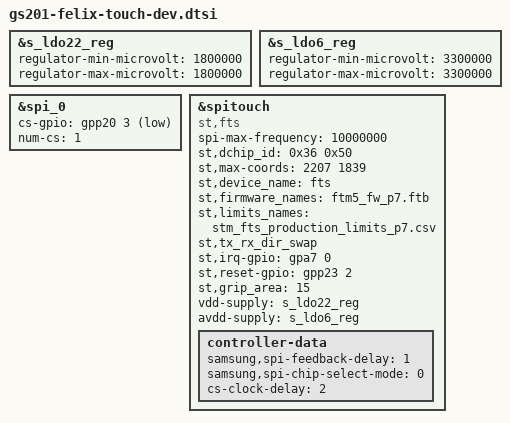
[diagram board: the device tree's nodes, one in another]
// SPDX-License-Identifier: GPL-2.0-only
/*
 * Google L10 touch device tree source
 *
 * Copyright 2022 Google Inc.
 *
 */

#include <arm64/exynos/exynos-pinctrl.h>

&s_ldo22_reg {
	regulator-min-microvolt = <1800000>;
	regulator-max-microvolt = <1800000>;
	/delete-property/ regulator-always-on;
};

&s_ldo6_reg {
	regulator-min-microvolt = <3300000>;
	regulator-max-microvolt = <3300000>;
	/delete-property/ regulator-always-on;
};

&spi_0 {
	cs-gpio = <&gpp20 3 GPIO_ACTIVE_LOW>;
	num-cs = <1>;
};

&spitouch {
	status = "ok";
	compatible = "st,fts";
	spi-max-frequency = <10000000>;
	st,dchip_id = /bits/ 8 <0x36 0x50>;
	st,max-coords = <2207 1839>;
	st,device_name = "fts";
	st,firmware_names = "ftm5_fw_p7.ftb";
	st,limits_names = "stm_fts_production_limits_p7.csv";
	/* st,panel_map = <&samsung_ana6707_f10 0>; */
	st,tx_rx_dir_swap;
	pinctrl-names = "pmx_ts_active", "pmx_ts_suspend";
	st,irq-gpio = <&gpa7 0 0>;
	st,reset-gpio = <&gpp23 2 0>;
	/* Either st,panel_map or st,max-coords should be used
	 * in the product touch dtsi */
	st,grip_area = /bits/ 8 <15>; /* Left and right grip rejection
					 area. Unit: pixels */
	vdd-supply = <&s_ldo22_reg>; /* VIO 1.8V, different from common. */
	avdd-supply = <&s_ldo6_reg>; /* AVDD 3.3V, different from common. */
	controller-data {
		samsung,spi-feedback-delay = <1>;
		samsung,spi-chip-select-mode = <0>;
		cs-clock-delay = <2>;
	};
};
